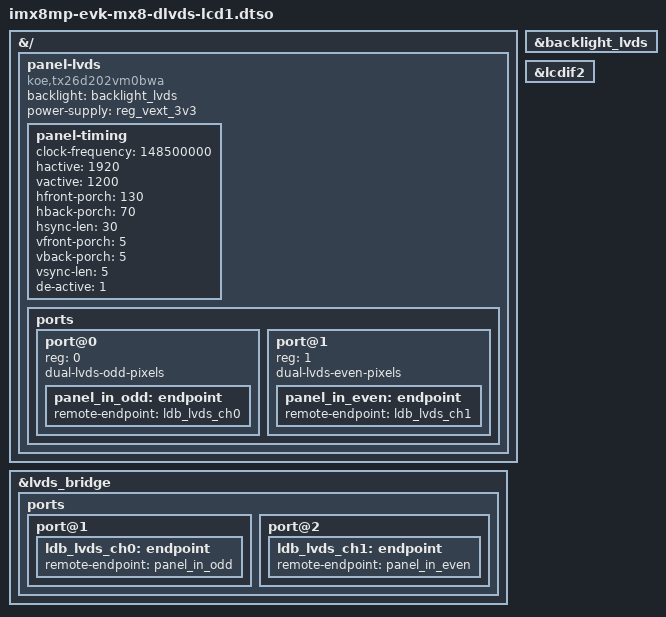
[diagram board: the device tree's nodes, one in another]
// SPDX-License-Identifier: (GPL-2.0+ OR MIT)
/*
 * Copyright 2024 NXP
 */

/dts-v1/;
/plugin/;

&{/} {
	panel-lvds {
		compatible = "koe,tx26d202vm0bwa";
		backlight = <&backlight_lvds>;
		power-supply = <&reg_vext_3v3>;

		panel-timing {
			clock-frequency = <148500000>;
			hactive = <1920>;
			vactive = <1200>;
			hfront-porch = <130>;
			hback-porch = <70>;
			hsync-len = <30>;
			vfront-porch = <5>;
			vback-porch = <5>;
			vsync-len = <5>;
			de-active = <1>;
		};

		ports {
			#address-cells = <1>;
			#size-cells = <0>;

			port@0 {
				reg = <0>;
				dual-lvds-odd-pixels;

				panel_in_odd: endpoint {
					remote-endpoint = <&ldb_lvds_ch0>;
				};
			};

			port@1 {
				reg = <1>;
				dual-lvds-even-pixels;

				panel_in_even: endpoint {
					remote-endpoint = <&ldb_lvds_ch1>;
				};
			};
		};
	};
};

&backlight_lvds {
	status = "okay";
};

&lcdif2 {
	status = "okay";
};

&lvds_bridge {
	status = "okay";

	ports {
		port@1 {
			ldb_lvds_ch0: endpoint {
				remote-endpoint = <&panel_in_odd>;
			};
		};

		port@2 {
			ldb_lvds_ch1: endpoint {
				remote-endpoint = <&panel_in_even>;
			};
		};
	};
};
